# ATSAML22J17A register map
Vendor: Microchip Technology; Series: SAML22; File version: 0
CPU: CM0+ r0p0, little endian, MPU, no FPU, VTOR, 2 interrupt priority bits, 26 interrupts
Registers are 32-bit, read-write, reset 0x0 unless marked. A register's access mark holds for its fields unless they carry their own. Offsets are from the block's base; [hi:lo] are bit positions; {n}, {i} and the like mark numbered series; 'fields as' and 'values as' point back to an identical list.

## OSCCTRL — Oscillators Control
Base 0x40001000
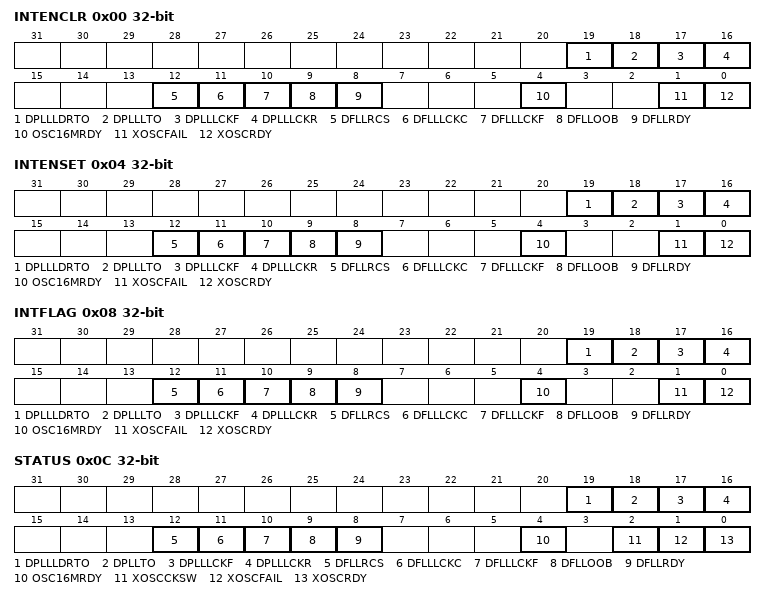
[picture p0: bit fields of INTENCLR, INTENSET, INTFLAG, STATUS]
0x00 INTENCLR write-1-clears — Interrupt Enable Clear
  [19] DPLLLDRTO — DPLL Ratio Ready Interrupt Enable
  [18] DPLLLTO — DPLL Time Out Interrupt Enable
  [17] DPLLLCKF — DPLL Lock Fall Interrupt Enable
  [16] DPLLLCKR — DPLL Lock Rise Interrupt Enable
  [12] DFLLRCS — DFLL Reference Clock Stopped Interrupt Enable
  [11] DFLLLCKC — DFLL Lock Coarse Interrupt Enable
  [10] DFLLLCKF — DFLL Lock Fine Interrupt Enable
  [9] DFLLOOB — DFLL Out Of Bounds Interrupt Enable
  [8] DFLLRDY — DFLL Ready Interrupt Enable
  [4] OSC16MRDY — OSC16M Ready Interrupt Enable
  [1] XOSCFAIL — XOSC Clock Failure Detector Interrupt Enable
  [0] XOSCRDY — XOSC Ready Interrupt Enable
0x04 INTENSET write-1-sets — Interrupt Enable Set
  fields as INTENCLR
0x08 INTFLAG write-1-clears — Interrupt Flag Status and Clear
  [19] DPLLLDRTO — DPLL Ratio Ready
  [18] DPLLLTO — DPLL Timeout
  [17] DPLLLCKF — DPLL Lock Fall
  [16] DPLLLCKR — DPLL Lock Rise
  [12] DFLLRCS — DFLL Reference Clock Stopped
  [11] DFLLLCKC — DFLL Lock Coarse
  [10] DFLLLCKF — DFLL Lock Fine
  [9] DFLLOOB — DFLL Out Of Bounds
  [8] DFLLRDY — DFLL Ready
  [4] OSC16MRDY — OSC16M Ready
  [1] XOSCFAIL — XOSC Clock Failure Detector
  [0] XOSCRDY — XOSC Ready
0x0C STATUS ro — Power and Clocks Status
  [19] DPLLLDRTO — DPLL Ratio Ready
  [18] DPLLTO — DPLL Timeout
  [17] DPLLLCKF — DPLL Lock Fall
  [16] DPLLLCKR — DPLL Lock Rise
  [12] DFLLRCS — DFLL Reference Clock Stopped
  [11] DFLLLCKC — DFLL Lock Coarse
  [10] DFLLLCKF — DFLL Lock Fine
  [9] DFLLOOB — DFLL Out Of Bounds
  [8] DFLLRDY — DFLL Ready
  [4] OSC16MRDY — OSC16M Ready
  [2] XOSCCKSW — XOSC Clock Switch
  [1] XOSCFAIL — XOSC Clock Failure Detector
  [0] XOSCRDY — XOSC Ready
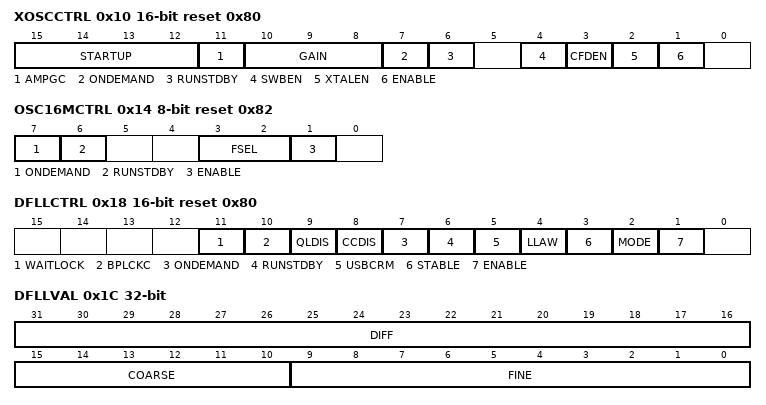
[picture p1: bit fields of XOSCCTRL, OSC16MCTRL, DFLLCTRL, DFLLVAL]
0x10 XOSCCTRL 16-bit reset 0x80 — External Multipurpose Crystal Oscillator (XOSC) Control
  [15:12] STARTUP — Start-Up Time
    0=CYCLE1 (31 us); 1=CYCLE2 (61 us); 2=CYCLE4 (122 us); 3=CYCLE8 (244 us); 4=CYCLE16 (488 us); 5=CYCLE32 (977 us); 6=CYCLE64 (1953 us); 7=CYCLE128 (3906 us); 8=CYCLE256 (7813 us); 9=CYCLE512 (15625 us); 10=CYCLE1024 (31250 us); 11=CYCLE2048 (62500 us); 12=CYCLE4096 (125000 us); 13=CYCLE8192 (250000 us); 14=CYCLE16384 (500000 us); 15=CYCLE32768 (1000000 us)
  [11] AMPGC — Automatic Amplitude Gain Control
  [10:8] GAIN — Oscillator Gain
    0=2 MHz; 1=4 MHz; 2=8 MHz; 3=16 MHz; 4=30 MHz
  [7] ONDEMAND — On Demand Control
  [6] RUNSTDBY — Run in Standby
  [4] SWBEN — Xosc Clock Switch Enable
  [3] CFDEN — Xosc Clock Failure Detecteor Enable
  [2] XTALEN — Crystal Oscillator Enable
  [1] ENABLE — Oscillator Enable
0x12 CFDPRESC 8-bit — Cloc Failure Detector Prescaler
  [2:0] CFDPRESC — Clock Failure Detector Prescaler
    0=DIV1 (OSC16M/1); 1=DIV2 (OSC16M/2); 2=DIV4 (OSC16M/4); 3=DIV8 (OSC16M/8); 4=DIV16 (OSC16M/16); 5=DIV32 (OSC16M/32); 6=DIV64 (OSC16M/64); 7=DIV128 (OSC16M/128)
0x13 EVCTRL 8-bit — Event Control
  [0] CFDEO — Clock Failure Detector Event Output Enable
0x14 OSC16MCTRL 8-bit reset 0x82 — 16MHz Internal Oscillator (OSC16M) Control
  [7] ONDEMAND — On Demand Control
  [6] RUNSTDBY — Run in Standby
  [3:2] FSEL — Oscillator Frequency Select
    0=4MHz; 1=8MHz; 2=12MHz; 3=16MHz
  [1] ENABLE — Oscillator Enable
0x18 DFLLCTRL 16-bit reset 0x80 — DFLL48M Control
  [11] WAITLOCK
  [10] BPLCKC — Bypass Coarse Lock
  [9] QLDIS — Quick Lock Disable
  [8] CCDIS — Chill Cycle Disable
  [7] ONDEMAND — On Demand Control
  [6] RUNSTDBY — Run in Standby
  [5] USBCRM — USB Clock Recovery Mode
  [4] LLAW — Lose Lock After Wake
  [3] STABLE — Stable DFLL Frequency
  [2] MODE — Operating Mode Selection
  [1] ENABLE — DFLL Enable
0x1C DFLLVAL — DFLL48M Value
  [31:16] DIFF — Multiplication Ratio Difference
  [15:10] COARSE — Coarse Value
  [9:0] FINE — Fine Value
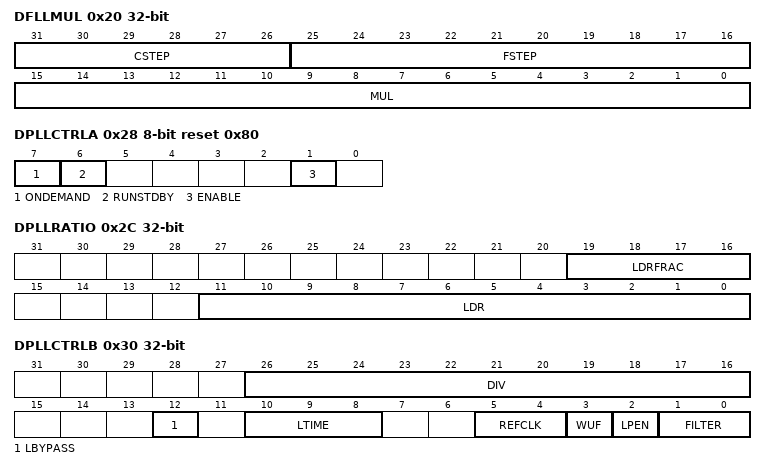
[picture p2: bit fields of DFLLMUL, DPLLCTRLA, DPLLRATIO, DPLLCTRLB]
0x20 DFLLMUL — DFLL48M Multiplier
  [31:26] CSTEP — Coarse Maximum Step
  [25:16] FSTEP — Fine Maximum Step
  [15:0] MUL — DFLL Multiply Factor
0x24 DFLLSYNC 8-bit — DFLL48M Synchronization
  [7] READREQ — Read Request
0x28 DPLLCTRLA 8-bit reset 0x80 — DPLL Control
  [7] ONDEMAND
  [6] RUNSTDBY — Run in Standby
  [1] ENABLE
0x2C DPLLRATIO — DPLL Ratio Control
  [19:16] LDRFRAC — Loop Divider Ratio Fractional Part
  [11:0] LDR — Loop Divider Ratio
0x30 DPLLCTRLB — Digital Core Configuration
  [26:16] DIV — Clock Divider
  [12] LBYPASS — Lock Bypass
  [10:8] LTIME — Lock Time
    0=DEFAULT (No time-out. Automatic lock.); {v}={v+4}MS (Time-out if no lock within {v+4}ms) (v=4..7)
  [5:4] REFCLK — Reference Clock Selection
    0=XOSC32K (XOSC32K clock reference); 1=XOSC (XOSC clock reference); 2=GCLK (GCLK clock reference)
  [3] WUF — Wake Up Fast
  [2] LPEN — Low-Power Enable
  [1:0] FILTER — Proportional Integral Filter Selection
    0=DEFAULT (Default filter mode); 1=LBFILT (Low bandwidth filter); 2=HBFILT (High bandwidth filter); 3=HDFILT (High damping filter)
0x34 DPLLPRESC 8-bit — DPLL Prescaler
  [1:0] PRESC — Output Clock Prescaler
    0=DIV1 (DPLL output is divided by 1); 1=DIV2 (DPLL output is divided by 2); 2=DIV4 (DPLL output is divided by 4)
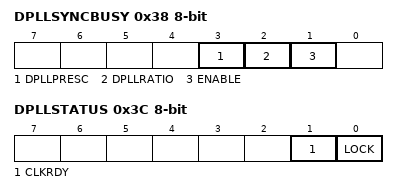
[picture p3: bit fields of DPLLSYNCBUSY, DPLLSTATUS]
0x38 DPLLSYNCBUSY 8-bit ro — DPLL Synchronization Busy
  [3] DPLLPRESC — DPLL Prescaler Synchronization Status
  [2] DPLLRATIO — DPLL Ratio Synchronization Status
  [1] ENABLE — DPLL Enable Synchronization Status
0x3C DPLLSTATUS 8-bit ro
  [1] CLKRDY — DPLL Clock Ready
  [0] LOCK — DPLL Lock Status

## Notices in the file
Copyright (c) 2026 Microchip Technology Inc.
SPDX-License-Identifier: Apache-2.0
Licensed under the Apache License, Version 2.0 (the "License");
you may not use this file except in compliance with the License.
You may obtain a copy of the License at
http://www.apache.org/licenses/LICENSE-2.0
Unless required by applicable law or agreed to in writing, software
distributed under the License is distributed on an "AS IS" BASIS,
WITHOUT WARRANTIES OR CONDITIONS OF ANY KIND, either express or implied.
See the License for the specific language governing permissions and
limitations under the License.
